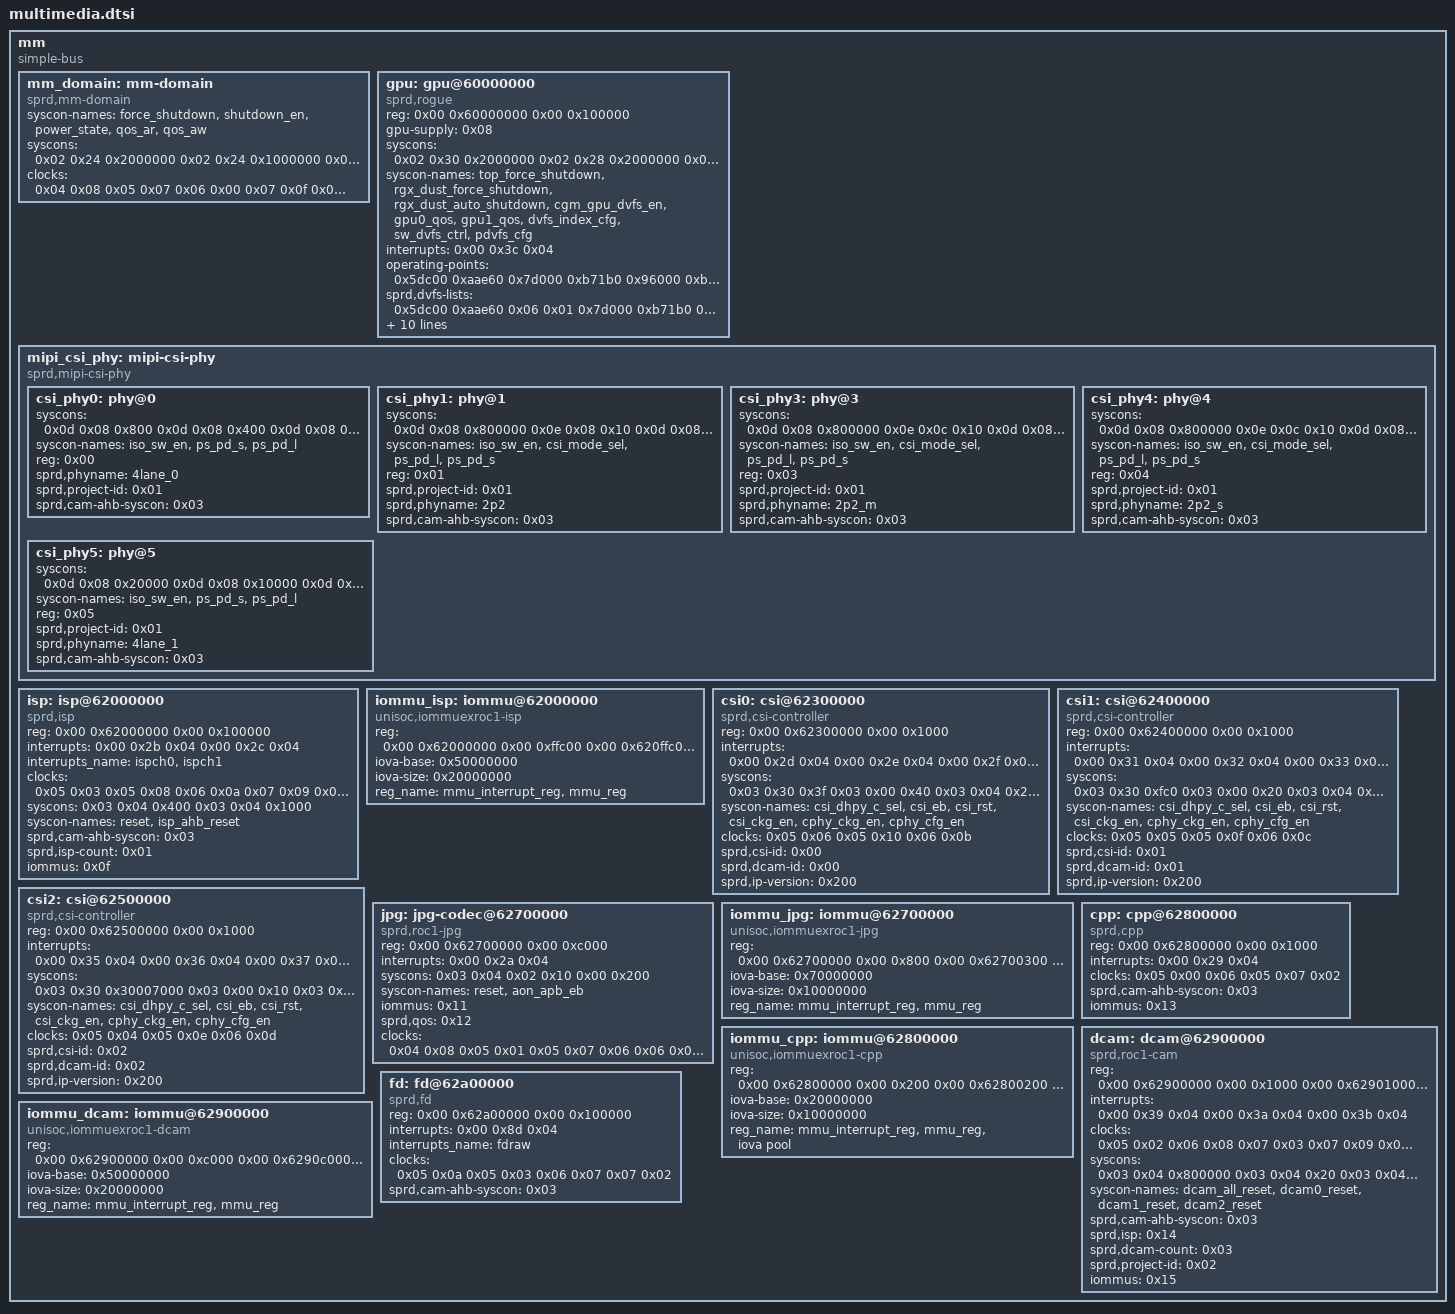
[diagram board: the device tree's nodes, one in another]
/*
 * iclass-c8pro hardware description; included in place from the board DTS.
 * Copyright (C) 2026 Evarentha - Linux 5.15 board port changes.
 */

		mm {
			compatible = "simple-bus";
			#address-cells = <0x02>;
			#size-cells = <0x02>;
			ranges;

			mm_domain: mm-domain {
				compatible = "sprd,mm-domain";
				syscon-names = "force_shutdown", "shutdown_en", "power_state", "qos_ar", "qos_aw";
				syscons = <0x02 0x24 0x2000000 0x02 0x24 0x1000000 0x02 0x588 0xff000000 0x03 0x0c 0xf0 0x03 0x0c 0x0f>;
				clock-names = "mm_eb", "mm_ahb_eb", "clk_mm_ahb", "clk_mm_ahb_parent", "mm_mtx_eb", "clk_mm_mtx", "clk_mm_mtx_parent", "clk_isppll";
				clocks = <0x04 0x08 0x05 0x07 0x06 0x00 0x07 0x0f 0x05 0x08 0x06 0x01 0x07 0x08 0x07 0x1b>;
				phandle = <0x141>;
			};

			gpu: gpu@60000000 {
				compatible = "sprd,rogue";
				reg = <0x00 0x60000000 0x00 0x100000>;
				gpu-supply = <0x08>;
				syscons = <0x02 0x30 0x2000000 0x02 0x28 0x2000000 0x02 0x28 0x1000000 0x09 0x34 0x01 0x09 0x10 0x1ffff 0x09 0x28 0x1ffff 0x0a 0x8c 0x07 0x0a 0x20 0x171 0x0a 0x3c 0x01>;
				syscon-names = "top_force_shutdown", "rgx_dust_force_shutdown", "rgx_dust_auto_shutdown", "cgm_gpu_dvfs_en", "gpu0_qos", "gpu1_qos", "dvfs_index_cfg", "sw_dvfs_ctrl", "pdvfs_cfg";
				interrupts = <0x00 0x3c 0x04>;
				operating-points = <0x5dc00 0xaae60 0x7d000 0xb71b0 0x96000 0xb71b0 0xbb800 0xc3500 0xc3500 0xc3500>;
				sprd,dvfs-lists = <0x5dc00 0xaae60 0x06 0x01 0x7d000 0xb71b0 0x07 0x01 0x96000 0xb71b0 0x08 0x01 0xbb800 0xc3500 0x09 0x01 0xc3500 0xc3500 0x0a 0x01>;
				sprd,dvfs-default = <0x00>;
				sprd,qos = <0x0b>;
				sprd,dvfs-scene-extreme = <0x02>;
				sprd,dvfs-scene-high = <0x01>;
				sprd,dvfs-scene-medium = <0x01>;
				sprd,dvfs-scene-low = <0x00>;
				sprd,dvfs-range-max = <0x02>;
				sprd,dvfs-range-min = <0x00>;
				clocks = <0x04 0x0a 0x0c 0x00 0x0c 0x01 0x0c 0x02 0x0c 0x03 0x0c 0x04 0x07 0x02 0x07 0x08 0x07 0x15 0x07 0x01 0x07 0x18>;
				phandle = <0x142>;
			};

			mipi_csi_phy: mipi-csi-phy {
				compatible = "sprd,mipi-csi-phy";
				#address-cells = <0x01>;
				#size-cells = <0x00>;
				ranges;
				status = "okay";
				phandle = <0x143>;

				csi_phy0: phy@0 {
					syscons = <0x0d 0x08 0x800 0x0d 0x08 0x400 0x0d 0x08 0x200>;
					syscon-names = "iso_sw_en", "ps_pd_s", "ps_pd_l";
					reg = <0x00>;
					sprd,phyname = "4lane_0";
					sprd,project-id = <0x01>;
					sprd,cam-ahb-syscon = <0x03>;
					status = "okay";
					phandle = <0x144>;
				};

				csi_phy1: phy@1 {
					syscons = <0x0d 0x08 0x800000 0x0e 0x08 0x10 0x0d 0x08 0x200000 0x0d 0x08 0x400000>;
					syscon-names = "iso_sw_en", "csi_mode_sel", "ps_pd_l", "ps_pd_s";
					reg = <0x01>;
					sprd,project-id = <0x01>;
					sprd,phyname = "2p2";
					sprd,cam-ahb-syscon = <0x03>;
					status = "okay";
					phandle = <0x145>;
				};

				csi_phy3: phy@3 {
					syscons = <0x0d 0x08 0x800000 0x0e 0x0c 0x10 0x0d 0x08 0x200000 0x0d 0x08 0x400000>;
					syscon-names = "iso_sw_en", "csi_mode_sel", "ps_pd_l", "ps_pd_s";
					reg = <0x03>;
					sprd,project-id = <0x01>;
					sprd,phyname = "2p2_m";
					sprd,cam-ahb-syscon = <0x03>;
					status = "okay";
					phandle = <0x146>;
				};

				csi_phy4: phy@4 {
					syscons = <0x0d 0x08 0x800000 0x0e 0x0c 0x10 0x0d 0x08 0x200000 0x0d 0x08 0x400000>;
					syscon-names = "iso_sw_en", "csi_mode_sel", "ps_pd_l", "ps_pd_s";
					reg = <0x04>;
					sprd,project-id = <0x01>;
					sprd,phyname = "2p2_s";
					sprd,cam-ahb-syscon = <0x03>;
					status = "okay";
					phandle = <0x147>;
				};

				csi_phy5: phy@5 {
					syscons = <0x0d 0x08 0x20000 0x0d 0x08 0x10000 0x0d 0x08 0x8000>;
					syscon-names = "iso_sw_en", "ps_pd_s", "ps_pd_l";
					reg = <0x05>;
					sprd,project-id = <0x01>;
					sprd,phyname = "4lane_1";
					sprd,cam-ahb-syscon = <0x03>;
					status = "okay";
					phandle = <0x148>;
				};
			};

			isp: isp@62000000 {
				compatible = "sprd,isp";
				reg = <0x00 0x62000000 0x00 0x100000>;
				interrupts = <0x00 0x2b 0x04 0x00 0x2c 0x04>;
				interrupts_name = "ispch0", "ispch1";
				clock-names = "isp_eb", "isp_axi_eb", "isp_clk", "isp_clk_256m", "isp_clk_307m2", "isp_clk_384m", "isp_clk_468m", "isp_clk_512m", "isp_clk_parent";
				clocks = <0x05 0x03 0x05 0x08 0x06 0x0a 0x07 0x09 0x07 0x0c 0x07 0x02 0x07 0x1b 0x07 0x08 0x07 0x08>;
				syscons = <0x03 0x04 0x400 0x03 0x04 0x1000>;
				syscon-names = "reset", "isp_ahb_reset";
				sprd,cam-ahb-syscon = <0x03>;
				sprd,isp-count = <0x01>;
				iommus = <0x0f>;
				status = "okay";
				phandle = <0x14>;
			};

			iommu_isp: iommu@62000000 {
				compatible = "unisoc,iommuexroc1-isp";
				reg = <0x00 0x62000000 0x00 0xffc00 0x00 0x620ffc00 0x00 0x400>;
				iova-base = <0x50000000>;
				iova-size = <0x20000000>;
				reg_name = "mmu_interrupt_reg", "mmu_reg";
				status = "okay";
				#iommu-cells = <0x00>;
				phandle = <0x0f>;
			};

			csi0: csi@62300000 {
				compatible = "sprd,csi-controller";
				reg = <0x00 0x62300000 0x00 0x1000>;
				interrupts = <0x00 0x2d 0x04 0x00 0x2e 0x04 0x00 0x2f 0x04 0x00 0x30 0x04>;
				syscons = <0x03 0x30 0x3f 0x03 0x00 0x40 0x03 0x04 0x200 0x03 0x08 0x20 0x03 0x08 0x100 0x10 0x13c 0x8000>;
				syscon-names = "csi_dhpy_c_sel", "csi_eb", "csi_rst", "csi_ckg_en", "cphy_ckg_en", "cphy_cfg_en";
				clock-names = "csi_eb", "mipi_csi_eb", "mipi_csi_src";
				clocks = <0x05 0x06 0x05 0x10 0x06 0x0b>;
				sprd,csi-id = <0x00>;
				sprd,dcam-id = <0x00>;
				sprd,ip-version = <0x200>;
				status = "okay";
				phandle = <0x96>;
			};

			csi1: csi@62400000 {
				compatible = "sprd,csi-controller";
				reg = <0x00 0x62400000 0x00 0x1000>;
				interrupts = <0x00 0x31 0x04 0x00 0x32 0x04 0x00 0x33 0x04 0x00 0x34 0x04>;
				syscons = <0x03 0x30 0xfc0 0x03 0x00 0x20 0x03 0x04 0x100 0x03 0x08 0x10 0x03 0x08 0x100 0x10 0x13c 0x8000>;
				syscon-names = "csi_dhpy_c_sel", "csi_eb", "csi_rst", "csi_ckg_en", "cphy_ckg_en", "cphy_cfg_en";
				clock-names = "csi_eb", "mipi_csi_eb", "mipi_csi_src";
				clocks = <0x05 0x05 0x05 0x0f 0x06 0x0c>;
				sprd,csi-id = <0x01>;
				sprd,dcam-id = <0x01>;
				sprd,ip-version = <0x200>;
				status = "okay";
				phandle = <0x99>;
			};

			csi2: csi@62500000 {
				compatible = "sprd,csi-controller";
				reg = <0x00 0x62500000 0x00 0x1000>;
				interrupts = <0x00 0x35 0x04 0x00 0x36 0x04 0x00 0x37 0x04 0x00 0x38 0x04>;
				syscons = <0x03 0x30 0x30007000 0x03 0x00 0x10 0x03 0x04 0x80 0x03 0x08 0x08 0x03 0x08 0x100 0x10 0x13c 0x8000>;
				syscon-names = "csi_dhpy_c_sel", "csi_eb", "csi_rst", "csi_ckg_en", "cphy_ckg_en", "cphy_cfg_en";
				clock-names = "csi_eb", "mipi_csi_eb", "mipi_csi_src";
				clocks = <0x05 0x04 0x05 0x0e 0x06 0x0d>;
				sprd,csi-id = <0x02>;
				sprd,dcam-id = <0x02>;
				sprd,ip-version = <0x200>;
				status = "okay";
				phandle = <0x149>;
			};

			jpg: jpg-codec@62700000 {
				compatible = "sprd,roc1-jpg";
				reg = <0x00 0x62700000 0x00 0xc000>;
				interrupts = <0x00 0x2a 0x04>;
				syscons = <0x03 0x04 0x02 0x10 0x00 0x200>;
				syscon-names = "reset", "aon_apb_eb";
				iommus = <0x11>;
				sprd,qos = <0x12>;
				status = "okay";
				clock-names = "jpg_domain_eb", "jpg_dev_eb", "jpg_ckg_eb", "jpg_clk", "clk_src_76m8", "clk_src_128m", "clk_src_256m", "clk_src_384m";
				clocks = <0x04 0x08 0x05 0x01 0x05 0x07 0x06 0x06 0x07 0x10 0x07 0x0a 0x07 0x09 0x07 0x02>;
				phandle = <0x14a>;
			};

			iommu_jpg: iommu@62700000 {
				compatible = "unisoc,iommuexroc1-jpg";
				reg = <0x00 0x62700000 0x00 0x800 0x00 0x62700300 0x00 0x80>;
				iova-base = <0x70000000>;
				iova-size = <0x10000000>;
				reg_name = "mmu_interrupt_reg", "mmu_reg";
				status = "okay";
				#iommu-cells = <0x00>;
				phandle = <0x11>;
			};

			cpp: cpp@62800000 {
				compatible = "sprd,cpp";
				reg = <0x00 0x62800000 0x00 0x1000>;
				interrupts = <0x00 0x29 0x04>;
				clock-names = "cpp_eb", "cpp_clk", "cpp_clk_parent";
				clocks = <0x05 0x00 0x06 0x05 0x07 0x02>;
				sprd,cam-ahb-syscon = <0x03>;
				iommus = <0x13>;
				status = "okay";
				phandle = <0x14b>;
			};

			iommu_cpp: iommu@62800000 {
				compatible = "unisoc,iommuexroc1-cpp";
				reg = <0x00 0x62800000 0x00 0x200 0x00 0x62800200 0x00 0x60>;
				iova-base = <0x20000000>;
				iova-size = <0x10000000>;
				reg_name = "mmu_interrupt_reg", "mmu_reg", "iova pool";
				status = "okay";
				#iommu-cells = <0x00>;
				phandle = <0x13>;
			};

			dcam: dcam@62900000 {
				compatible = "sprd,roc1-cam";
				reg = <0x00 0x62900000 0x00 0x1000 0x00 0x62901000 0x00 0x1000 0x00 0x62902000 0x00 0x1000 0x00 0x62903000 0x00 0x1000>;
				reg-names = "dcam0_reg", "dcam1_reg", "dcam2_reg", "axi_ctrl_reg";
				interrupts = <0x00 0x39 0x04 0x00 0x3a 0x04 0x00 0x3b 0x04>;
				interrupt-names = "dcam0", "dcam1", "dcam2";
				clock-names = "dcam_eb", "dcam_clk", "dcam_clk_192m", "dcam_clk_256m", "dcam_clk_307m2", "dcam_clk_384m", "dcam_clk_468m", "dcam_clk_parent", "dcam_axi_eb", "dcam_axi_clk", "dcam_axi_clk_256m", "dcam_axi_clk_307m2", "dcam_axi_clk_384m", "dcam_axi_clk_468m", "dcam_axi_clk_parent";
				clocks = <0x05 0x02 0x06 0x08 0x07 0x03 0x07 0x09 0x07 0x0c 0x07 0x02 0x07 0x1b 0x07 0x1b 0x05 0x11 0x06 0x09 0x07 0x09 0x07 0x0c 0x07 0x02 0x07 0x1b 0x07 0x1b>;
				syscons = <0x03 0x04 0x800000 0x03 0x04 0x20 0x03 0x04 0x10 0x03 0x04 0x08>;
				syscon-names = "dcam_all_reset", "dcam0_reset", "dcam1_reset", "dcam2_reset";
				sprd,cam-ahb-syscon = <0x03>;
				sprd,isp = <0x14>;
				sprd,dcam-count = <0x03>;
				sprd,project-id = <0x02>;
				iommus = <0x15>;
				status = "okay";
				phandle = <0x14c>;
			};

			iommu_dcam: iommu@62900000 {
				compatible = "unisoc,iommuexroc1-dcam";
				reg = <0x00 0x62900000 0x00 0xc000 0x00 0x6290c000 0x00 0x60>;
				iova-base = <0x50000000>;
				iova-size = <0x20000000>;
				reg_name = "mmu_interrupt_reg", "mmu_reg";
				status = "okay";
				#iommu-cells = <0x00>;
				phandle = <0x15>;
			};

			fd: fd@62a00000 {
				compatible = "sprd,fd";
				reg = <0x00 0x62a00000 0x00 0x100000>;
				interrupts = <0x00 0x8d 0x04>;
				interrupts_name = "fdraw";
				clock-names = "fd_eb", "fd_axi_eb", "fd_clk", "fd_clk_parent";
				clocks = <0x05 0x0a 0x05 0x03 0x06 0x07 0x07 0x02>;
				sprd,cam-ahb-syscon = <0x03>;
				status = "okay";
				phandle = <0x14d>;
			};
		};

